AUTOSAR XML (schema 4-0-3)
standard types defined: Boolean, UInt16, UInt32, UInt8
package /AUTOSAR_Platform/DataConstrs
  range DC_Boolean: raw 0..1
  range DC_UInt16: raw 0..65535
  range DC_UInt8: raw 0..255
package /PATAC/MSM/ComponentTypes
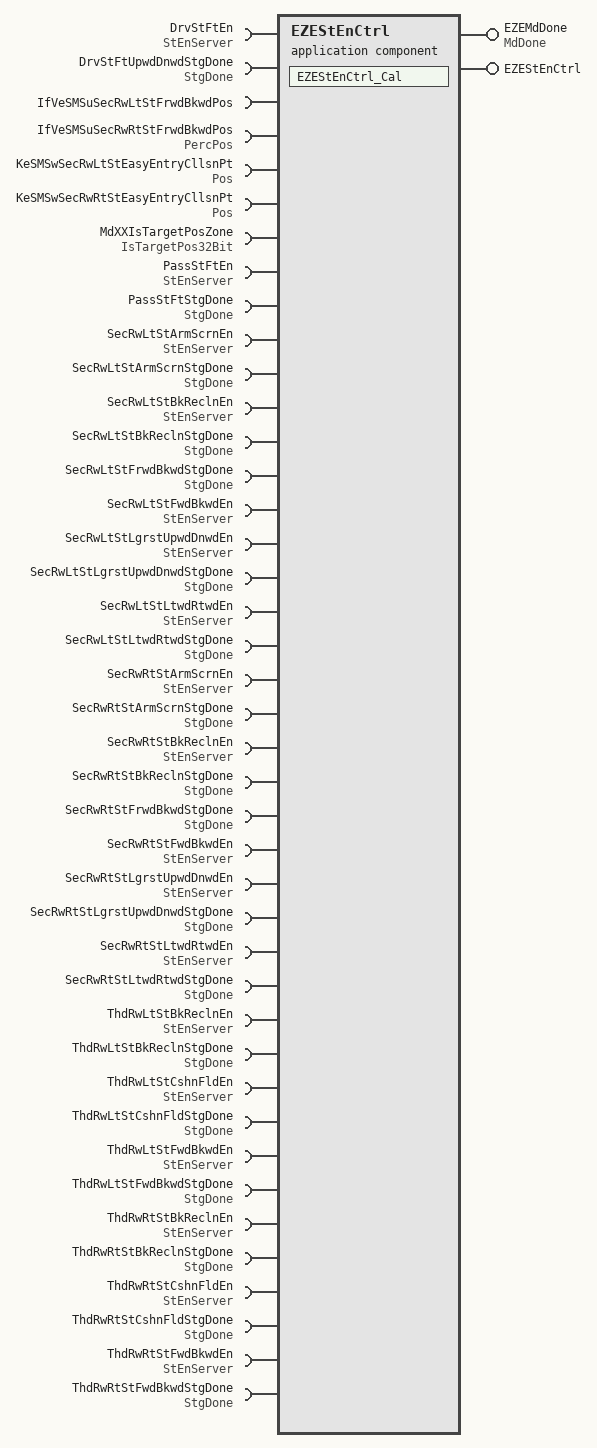
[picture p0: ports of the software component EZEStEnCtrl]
  application sw component type EZEStEnCtrl
    provide port EZEMdDone: nonqueued-sender-com-spec{data-element=MdDone/Val, init-value=0}, provided-interface=MdDone
    provide port EZEStEnCtrl: server-com-spec{operation=Cal, queue-length=1}, provided-interface=EZEStEnCtrl
    41 x require port:
      DrvStFtEn: required-com-specs=[Clear, Get, Set], required-interface=StEnServer
      DrvStFtUpwdDnwdStgDone: nonqueued-receiver-com-spec{data-element=StgDone/Val, filter=data-filter-type=ALWAYS, init-value=0}, required-interface=StgDone
      IfVeSMSuSecRwLtStFrwdBkwdPos: nonqueued-receiver-com-spec{data-element=IfVeSMSuSecRwLtStFrwdBkwdPos/Val, filter=data-filter-type=ALWAYS, init-value=0}, required-interface=IfVeSMSuSecRwLtStFrwdBkwdPos
      IfVeSMSuSecRwRtStFrwdBkwdPos: nonqueued-receiver-com-spec{data-element=PercPos/Val, filter=data-filter-type=ALWAYS, init-value=0}, required-interface=PercPos
      KeSMSwSecRwLtStEasyEntryCllsnPt: parameter-require-com-spec{init-value=20, parameter=Val}, required-interface=Pos
      KeSMSwSecRwRtStEasyEntryCllsnPt: parameter-require-com-spec{init-value=20, parameter=Val}, required-interface=Pos
      MdXXIsTargetPosZone: nonqueued-receiver-com-spec{data-element=IsTargetPos32Bit/Val, filter=data-filter-type=ALWAYS, init-value=0}, required-interface=IsTargetPos32Bit
      PassStFtEn: required-com-specs=[Clear, Get, Set], required-interface=StEnServer
      PassStFtStgDone: nonqueued-receiver-com-spec{data-element=StgDone/Val, filter=data-filter-type=ALWAYS, init-value=0}, required-interface=StgDone
      SecRwLtStArmScrnEn: required-com-specs=[Clear, Get, Set], required-interface=StEnServer
      SecRwLtStArmScrnStgDone: nonqueued-receiver-com-spec{data-element=StgDone/Val, filter=data-filter-type=ALWAYS, init-value=0}, required-interface=StgDone
      SecRwLtStBkReclnEn: required-com-specs=[Clear, Get, Set], required-interface=StEnServer
      SecRwLtStBkReclnStgDone: nonqueued-receiver-com-spec{data-element=StgDone/Val, filter=data-filter-type=ALWAYS, init-value=0}, required-interface=StgDone
      SecRwLtStFrwdBkwdStgDone: nonqueued-receiver-com-spec{data-element=StgDone/Val, filter=data-filter-type=ALWAYS, init-value=0}, required-interface=StgDone
      SecRwLtStFwdBkwdEn: required-com-specs=[Clear, Get, Set], required-interface=StEnServer
      SecRwLtStLgrstUpwdDnwdEn: required-com-specs=[Clear, Get, Set], required-interface=StEnServer
      SecRwLtStLgrstUpwdDnwdStgDone: nonqueued-receiver-com-spec{data-element=StgDone/Val, filter=data-filter-type=ALWAYS, init-value=0}, required-interface=StgDone
      SecRwLtStLtwdRtwdEn: required-com-specs=[Clear, Get, Set], required-interface=StEnServer
      SecRwLtStLtwdRtwdStgDone: nonqueued-receiver-com-spec{data-element=StgDone/Val, filter=data-filter-type=ALWAYS, init-value=0}, required-interface=StgDone
      SecRwRtStArmScrnEn: required-com-specs=[Clear, Get, Set], required-interface=StEnServer
      SecRwRtStArmScrnStgDone: nonqueued-receiver-com-spec{data-element=StgDone/Val, filter=data-filter-type=ALWAYS, init-value=0}, required-interface=StgDone
      SecRwRtStBkReclnEn: required-com-specs=[Clear, Get, Set], required-interface=StEnServer
      SecRwRtStBkReclnStgDone: nonqueued-receiver-com-spec{data-element=StgDone/Val, filter=data-filter-type=ALWAYS, init-value=0}, required-interface=StgDone
      SecRwRtStFrwdBkwdStgDone: nonqueued-receiver-com-spec{data-element=StgDone/Val, filter=data-filter-type=ALWAYS, init-value=0}, required-interface=StgDone
      SecRwRtStFwdBkwdEn: required-com-specs=[Clear, Get, Set], required-interface=StEnServer
      SecRwRtStLgrstUpwdDnwdEn: required-com-specs=[Clear, Get, Set], required-interface=StEnServer
      SecRwRtStLgrstUpwdDnwdStgDone: nonqueued-receiver-com-spec{data-element=StgDone/Val, filter=data-filter-type=ALWAYS, init-value=0}, required-interface=StgDone
      SecRwRtStLtwdRtwdEn: required-com-specs=[Clear, Get, Set], required-interface=StEnServer
      SecRwRtStLtwdRtwdStgDone: nonqueued-receiver-com-spec{data-element=StgDone/Val, filter=data-filter-type=ALWAYS, init-value=0}, required-interface=StgDone
      ThdRwLtStBkReclnEn: required-com-specs=[Clear, Get, Set], required-interface=StEnServer
      ThdRwLtStBkReclnStgDone: nonqueued-receiver-com-spec{data-element=StgDone/Val, filter=data-filter-type=ALWAYS, init-value=0}, required-interface=StgDone
      ThdRwLtStCshnFldEn: required-com-specs=[Clear, Get, Set], required-interface=StEnServer
      ThdRwLtStCshnFldStgDone: nonqueued-receiver-com-spec{data-element=StgDone/Val, filter=data-filter-type=ALWAYS, init-value=0}, required-interface=StgDone
      ThdRwLtStFwdBkwdEn: required-com-specs=[Clear, Get, Set], required-interface=StEnServer
      ThdRwLtStFwdBkwdStgDone: nonqueued-receiver-com-spec{data-element=StgDone/Val, filter=data-filter-type=ALWAYS, init-value=0}, required-interface=StgDone
      ThdRwRtStBkReclnEn: required-com-specs=[Clear, Get, Set], required-interface=StEnServer
      ThdRwRtStBkReclnStgDone: nonqueued-receiver-com-spec{data-element=StgDone/Val, filter=data-filter-type=ALWAYS, init-value=0}, required-interface=StgDone
      ThdRwRtStCshnFldEn: required-com-specs=[Clear, Get, Set], required-interface=StEnServer
      ThdRwRtStCshnFldStgDone: nonqueued-receiver-com-spec{data-element=StgDone/Val, filter=data-filter-type=ALWAYS, init-value=0}, required-interface=StgDone
      ThdRwRtStFwdBkwdEn: required-com-specs=[Clear, Get, Set], required-interface=StEnServer
      ThdRwRtStFwdBkwdStgDone: nonqueued-receiver-com-spec{data-element=StgDone/Val, filter=data-filter-type=ALWAYS, init-value=0}, required-interface=StgDone
    behavior EZEStEnCtrl_InternalBehavior
      operation invoked event OIT_EZEStEnCtrl_Cal_EZEStEnCtrl_Cal: start-on-event=EZEStEnCtrl_Cal, operation=EZEStEnCtrl.Cal
      runnable EZEStEnCtrl_Cal
        data-receive-point-by-arguments:
          21 x access:
            REC_DrvStFtUpwdDnwdStgDone_Val: accessed-variable=DrvStFtUpwdDnwdStgDone.Val
            REC_IfVeSMSuSecRwLtStFrwdBkwdPos_Val: accessed-variable=IfVeSMSuSecRwLtStFrwdBkwdPos.Val
            REC_IfVeSMSuSecRwRtStFrwdBkwdPos_Val: accessed-variable=IfVeSMSuSecRwRtStFrwdBkwdPos.Val
            REC_MdXXIsTargetPosZone_Val: accessed-variable=MdXXIsTargetPosZone.Val
            REC_PassStFtStgDone_Val: accessed-variable=PassStFtStgDone.Val
            REC_SecRwLtStArmScrnStgDone_Val: accessed-variable=SecRwLtStArmScrnStgDone.Val
            REC_SecRwLtStBkReclnStgDone_Val: accessed-variable=SecRwLtStBkReclnStgDone.Val
            REC_SecRwLtStFrwdBkwdStgDone_Val: accessed-variable=SecRwLtStFrwdBkwdStgDone.Val
            REC_SecRwLtStLgrstUpwdDnwdStgDone_Val: accessed-variable=SecRwLtStLgrstUpwdDnwdStgDone.Val
            REC_SecRwLtStLtwdRtwdStgDone_Val: accessed-variable=SecRwLtStLtwdRtwdStgDone.Val
            REC_SecRwRtStArmScrnStgDone_Val: accessed-variable=SecRwRtStArmScrnStgDone.Val
            REC_SecRwRtStBkReclnStgDone_Val: accessed-variable=SecRwRtStBkReclnStgDone.Val
            REC_SecRwRtStFrwdBkwdStgDone_Val: accessed-variable=SecRwRtStFrwdBkwdStgDone.Val
            REC_SecRwRtStLgrstUpwdDnwdStgDone_Val: accessed-variable=SecRwRtStLgrstUpwdDnwdStgDone.Val
            REC_SecRwRtStLtwdRtwdStgDone_Val: accessed-variable=SecRwRtStLtwdRtwdStgDone.Val
            REC_ThdRwLtStBkReclnStgDone_Val: accessed-variable=ThdRwLtStBkReclnStgDone.Val
            REC_ThdRwLtStCshnFldStgDone_Val: accessed-variable=ThdRwLtStCshnFldStgDone.Val
            REC_ThdRwLtStFwdBkwdStgDone_Val: accessed-variable=ThdRwLtStFwdBkwdStgDone.Val
            REC_ThdRwRtStBkReclnStgDone_Val: accessed-variable=ThdRwRtStBkReclnStgDone.Val
            REC_ThdRwRtStCshnFldStgDone_Val: accessed-variable=ThdRwRtStCshnFldStgDone.Val
            REC_ThdRwRtStFwdBkwdStgDone_Val: accessed-variable=ThdRwRtStFwdBkwdStgDone.Val
        data-send-points:
          access SEND_EZEMdDone_Val: accessed-variable=EZEMdDone.Val
        parameter access PA_KeSMSwSecRwLtStEasyEntryCllsnPt_Val: accessed-parameter=KeSMSwSecRwLtStEasyEntryCllsnPt.Val
        parameter access PA_KeSMSwSecRwRtStEasyEntryCllsnPt_Val: accessed-parameter=KeSMSwSecRwRtStEasyEntryCllsnPt.Val
        36 x sync call, all with timeout=0:
          SC_DrvStFtEn_Clear: operation=DrvStFtEn.Clear
          SC_DrvStFtEn_Set: operation=DrvStFtEn.Set
          SC_PassStFtEn_Clear: operation=PassStFtEn.Clear
          SC_PassStFtEn_Set: operation=PassStFtEn.Set
          SC_SecRwLtStArmScrnEn_Clear: operation=SecRwLtStArmScrnEn.Clear
          SC_SecRwLtStArmScrnEn_Set: operation=SecRwLtStArmScrnEn.Set
          SC_SecRwLtStBkReclnEn_Clear: operation=SecRwLtStBkReclnEn.Clear
          SC_SecRwLtStBkReclnEn_Set: operation=SecRwLtStBkReclnEn.Set
          SC_SecRwLtStFwdBkwdEn_Clear: operation=SecRwLtStFwdBkwdEn.Clear
          SC_SecRwLtStFwdBkwdEn_Set: operation=SecRwLtStFwdBkwdEn.Set
          SC_SecRwLtStLgrstUpwdDnwdEn_Clear: operation=SecRwLtStLgrstUpwdDnwdEn.Clear
          SC_SecRwLtStLgrstUpwdDnwdEn_Set: operation=SecRwLtStLgrstUpwdDnwdEn.Set
          SC_SecRwLtStLtwdRtwdEn_Clear: operation=SecRwLtStLtwdRtwdEn.Clear
          SC_SecRwLtStLtwdRtwdEn_Set: operation=SecRwLtStLtwdRtwdEn.Set
          SC_SecRwRtStArmScrnEn_Clear: operation=SecRwRtStArmScrnEn.Clear
          SC_SecRwRtStArmScrnEn_Set: operation=SecRwRtStArmScrnEn.Set
          SC_SecRwRtStBkReclnEn_Clear: operation=SecRwRtStBkReclnEn.Clear
          SC_SecRwRtStBkReclnEn_Set: operation=SecRwRtStBkReclnEn.Set
          SC_SecRwRtStFwdBkwdEn_Clear: operation=SecRwRtStFwdBkwdEn.Clear
          SC_SecRwRtStFwdBkwdEn_Set: operation=SecRwRtStFwdBkwdEn.Set
          SC_SecRwRtStLgrstUpwdDnwdEn_Clear: operation=SecRwRtStLgrstUpwdDnwdEn.Clear
          SC_SecRwRtStLgrstUpwdDnwdEn_Set: operation=SecRwRtStLgrstUpwdDnwdEn.Set
          SC_SecRwRtStLtwdRtwdEn_Clear: operation=SecRwRtStLtwdRtwdEn.Clear
          SC_SecRwRtStLtwdRtwdEn_Set: operation=SecRwRtStLtwdRtwdEn.Set
          SC_ThdRwLtStBkReclnEn_Clear: operation=ThdRwLtStBkReclnEn.Clear
          SC_ThdRwLtStBkReclnEn_Set: operation=ThdRwLtStBkReclnEn.Set
          SC_ThdRwLtStCshnFldEn_Clear: operation=ThdRwLtStCshnFldEn.Clear
          SC_ThdRwLtStCshnFldEn_Set: operation=ThdRwLtStCshnFldEn.Set
          SC_ThdRwLtStFwdBkwdEn_Clear: operation=ThdRwLtStFwdBkwdEn.Clear
          SC_ThdRwLtStFwdBkwdEn_Set: operation=ThdRwLtStFwdBkwdEn.Set
          SC_ThdRwRtStBkReclnEn_Clear: operation=ThdRwRtStBkReclnEn.Clear
          SC_ThdRwRtStBkReclnEn_Set: operation=ThdRwRtStBkReclnEn.Set
          SC_ThdRwRtStCshnFldEn_Clear: operation=ThdRwRtStCshnFldEn.Clear
          SC_ThdRwRtStCshnFldEn_Set: operation=ThdRwRtStCshnFldEn.Set
          SC_ThdRwRtStFwdBkwdEn_Clear: operation=ThdRwRtStFwdBkwdEn.Clear
          SC_ThdRwRtStFwdBkwdEn_Set: operation=ThdRwRtStFwdBkwdEn.Set
  swc implementation EZEStEnCtrl_Implementation: behavior=EZEStEnCtrl_InternalBehavior
    code-descriptors:
      code Default: artifact-descriptors=autosar-engineering-object={short-label=Default, category=SWSRC}
package /PATAC/MSM/ModeAdjust/CalPortInterface
  parameter interface Pos
    parameter data prototype Val: sw-calibration-access=READ-WRITE, type=UInt16
package /PATAC/MSM/ModeAdjust/PortInterface
  client server interface EZEStEnCtrl
    operation Cal
  client server interface StEnServer
    operation Clear
      arg data: type=UInt8, direction=IN, server-argument-impl-policy=USE-ARGUMENT-TYPE
    operation Get
      arg data: type=UInt32, direction=OUT, server-argument-impl-policy=USE-ARGUMENT-TYPE
    operation Set
      arg data: type=UInt8, direction=IN, server-argument-impl-policy=USE-ARGUMENT-TYPE
  4 x sender receiver interface:
    IsTargetPos32Bit: invalidation-policy{data-element=IsTargetPos32Bit/Val, handle-invalid=DONT-INVALIDATE}
      data Val: type=UInt32
    MdDone: invalidation-policy{data-element=MdDone/Val, handle-invalid=DONT-INVALIDATE}
      data Val: type=UInt8
    PercPos: invalidation-policy{data-element=PercPos/Val, handle-invalid=DONT-INVALIDATE}
      data Val: type=UInt16
    StgDone: invalidation-policy{data-element=StgDone/Val, handle-invalid=DONT-INVALIDATE}
      data Val: type=Boolean
package /PATAC/MSM/PortInterfaces
  sender receiver interface IfVeSMSuSecRwLtStFrwdBkwdPos: invalidation-policy{data-element=IfVeSMSuSecRwLtStFrwdBkwdPos/Val, handle-invalid=DONT-INVALIDATE}
    data Val: type=UInt16
